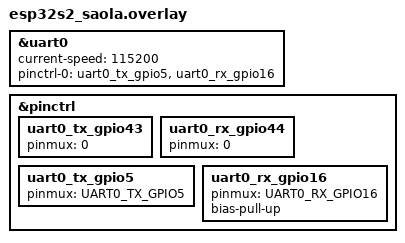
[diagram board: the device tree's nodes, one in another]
&uart0 {
        status = "okay";
        current-speed = <115200>;
        pinctrl-0 = <&uart0_tx_gpio5 &uart0_rx_gpio16>;
        pinctrl-names = "default";
};

&pinctrl {
        uart0_tx_gpio43: uart0_tx_gpio43 {
                pinmux = <0>;
        };

        uart0_rx_gpio44: uart0_rx_gpio44 {
                pinmux = <0>;
        };

	uart0_tx_gpio5: uart0_tx_gpio5 {
		pinmux = <UART0_TX_GPIO5>;
	};

	uart0_rx_gpio16: uart0_rx_gpio16 {
		pinmux = <UART0_RX_GPIO16>;
		bias-pull-up;
	};
};
